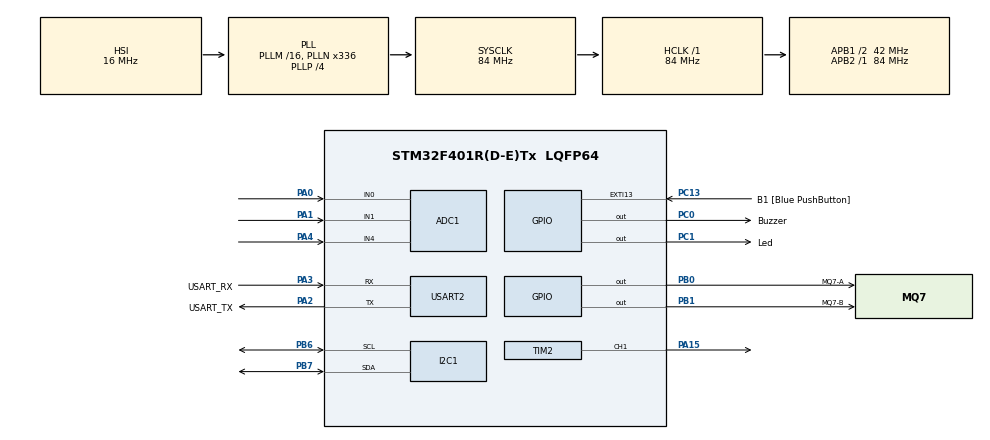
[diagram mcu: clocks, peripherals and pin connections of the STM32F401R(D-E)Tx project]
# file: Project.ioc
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ADC1.Channel-0\#ChannelRegularConversion=ADC_CHANNEL_0
ADC1.Channel-1\#ChannelRegularConversion=ADC_CHANNEL_1
ADC1.Channel-2\#ChannelRegularConversion=ADC_CHANNEL_4
ADC1.ContinuousConvMode=ENABLE
ADC1.DMAContinuousRequests=ENABLE
ADC1.DiscontinuousConvMode=DISABLE
ADC1.NbrOfConversion=3
ADC1.NbrOfConversionFlag=1
ADC1.Rank-0\#ChannelRegularConversion=1
ADC1.Rank-1\#ChannelRegularConversion=2
ADC1.Rank-2\#ChannelRegularConversion=3
ADC1.SamplingTime-0\#ChannelRegularConversion=ADC_SAMPLETIME_480CYCLES
ADC1.SamplingTime-1\#ChannelRegularConversion=ADC_SAMPLETIME_480CYCLES
ADC1.SamplingTime-2\#ChannelRegularConversion=ADC_SAMPLETIME_480CYCLES
ADC1.ScanConvMode=ENABLE
ADC1.master=1
Dma.ADC1.0.Direction=DMA_PERIPH_TO_MEMORY
Dma.ADC1.0.FIFOMode=DMA_FIFOMODE_DISABLE
Dma.ADC1.0.Instance=DMA2_Stream0
Dma.ADC1.0.MemDataAlignment=DMA_MDATAALIGN_HALFWORD
Dma.ADC1.0.MemInc=DMA_MINC_ENABLE
Dma.ADC1.0.Mode=DMA_CIRCULAR
Dma.ADC1.0.PeriphDataAlignment=DMA_PDATAALIGN_HALFWORD
Dma.ADC1.0.PeriphInc=DMA_PINC_DISABLE
Dma.ADC1.0.Priority=DMA_PRIORITY_LOW
Dma.Request0=ADC1
Mcu.Family=STM32F4
Mcu.Name=STM32F401R(D-E)Tx
Mcu.Package=LQFP64
NVIC.DMA2_Stream0_IRQn=true\:0\:0\:false\:false\:true\:false\:true\:true
NVIC.PriorityGroup=NVIC_PRIORITYGROUP_4
PA0-WKUP.Signal=ADCx_IN0
PA1.Signal=ADCx_IN1
PA13.GPIO_Label=TMS
PA13.Mode=Serial_Wire
PA13.Signal=SYS_JTMS-SWDIO
PA14.GPIO_Label=TCK
PA14.Mode=Serial_Wire
PA14.Signal=SYS_JTCK-SWCLK
PA15.Signal=S_TIM2_CH1_ETR
PA2.GPIO_Label=USART_TX
PA2.GPIO_Mode=GPIO_MODE_AF_PP
PA2.GPIO_PuPd=GPIO_NOPULL
PA2.GPIO_Speed=GPIO_SPEED_FREQ_LOW
PA2.Mode=Asynchronous
PA2.Signal=USART2_TX
PA3.GPIO_Label=USART_RX
PA3.GPIO_Mode=GPIO_MODE_AF_PP
PA3.GPIO_PuPd=GPIO_NOPULL
PA3.GPIO_Speed=GPIO_SPEED_FREQ_LOW
PA3.Mode=Asynchronous
PA3.Signal=USART2_RX
PA4.Signal=ADCx_IN4
PB0.GPIO_Label=MQ7-A
PB0.Signal=GPIO_Output
PB1.GPIO_Label=MQ7-B
PB1.Signal=GPIO_Output
PB3.GPIO_Label=SWO
PB3.Signal=SYS_JTDO-SWO
PB6.Mode=I2C
PB6.Signal=I2C1_SCL
PB7.Mode=I2C
PB7.Signal=I2C1_SDA
PC0.GPIO_Label=Buzzer
PC0.Signal=GPIO_Output
PC1.GPIO_Label=Led
PC1.Signal=GPIO_Output
PC13-ANTI_TAMP.GPIO_Label=B1 [Blue PushButton]
PC13-ANTI_TAMP.GPIO_ModeDefaultEXTI=GPIO_MODE_IT_FALLING
PC13-ANTI_TAMP.GPIO_PuPd=GPIO_NOPULL
PC13-ANTI_TAMP.Signal=GPXTI13
PC14-OSC32_IN.Mode=LSE-External-Oscillator
PC14-OSC32_IN.Signal=RCC_OSC32_IN
PC15-OSC32_OUT.Mode=LSE-External-Oscillator
PC15-OSC32_OUT.Signal=RCC_OSC32_OUT
PH0\ -\ OSC_IN.Mode=HSE-External-Clock-Source
PH0\ -\ OSC_IN.Signal=RCC_OSC_IN
PH1\ -\ OSC_OUT.Mode=HSE-External-Clock-Source
PH1\ -\ OSC_OUT.Signal=RCC_OSC_OUT
ProjectManager.HeapSize=0x200
ProjectManager.StackSize=0x400
ProjectManager.TargetToolchain=STM32CubeIDE
RCC.48MHZClocksFreq_Value=48000000
RCC.AHBFreq_Value=84000000
RCC.APB1CLKDivider=RCC_HCLK_DIV2
RCC.APB1Freq_Value=42000000
RCC.APB1TimFreq_Value=84000000
RCC.APB2Freq_Value=84000000
RCC.APB2TimFreq_Value=84000000
RCC.CortexFreq_Value=84000000
RCC.HCLKFreq_Value=84000000
RCC.HSE_VALUE=8000000
RCC.HSI_VALUE=16000000
RCC.PLLN=336
RCC.PLLP=RCC_PLLP_DIV4
RCC.PLLQ=7
RCC.SYSCLKFreq_VALUE=84000000
RCC.SYSCLKSource=RCC_SYSCLKSOURCE_PLLCLK
RCC.VCOOutputFreq_Value=336000000
SH.ADCx_IN0.0=ADC1_IN0,IN0
SH.ADCx_IN1.0=ADC1_IN1,IN1
SH.ADCx_IN4.0=ADC1_IN4,IN4
SH.S_TIM2_CH1_ETR.0=TIM2_CH1,PWM Generation1 CH1
TIM2.Channel-PWM\ Generation1\ CH1=TIM_CHANNEL_1
TIM2.Period=999
TIM2.Prescaler=84-1
USART2.VirtualMode=VM_ASYNC
VP_TIM2_VS_ClockSourceINT.Mode=Internal
board=NUCLEO-F401RE

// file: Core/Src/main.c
/* USER CODE BEGIN Header */
/**
  ******************************************************************************
  * @file           : main.c
  * @brief          : Main program body
  ******************************************************************************
  */
/* USER CODE END Header */
#include "main.h"

/* USER CODE BEGIN Includes */
#include <stdio.h>
#include "periph_led_buzzer.h"
#include "fan_pwm.h"
#include "sensor_raw.h"
#include "adc_dma.h"
#include "temp_sensor.h"
/* USER CODE END Includes */

ADC_HandleTypeDef hadc1;
DMA_HandleTypeDef hdma_adc1;

I2C_HandleTypeDef hi2c1;

TIM_HandleTypeDef htim2;

UART_HandleTypeDef huart2;

/* USER CODE BEGIN PV */
/* --- BIẾN ĐỊNH THỜI ĐA NHIỆM --- */
uint32_t last_mq7_cycle = 0;
uint32_t last_sensor_read = 0;
uint8_t current_pwm = 0;
/* --- BIẾN LƯU TRỮ DỮ LIỆU --- */
float current_temp = 0.0;
uint16_t mq135_raw = 0;
uint16_t mq7_raw = 0;
SHT30_Data_t sht30_data;

/* --- BIẾN PID ĐIỀU KHIỂN QUẠT --- */
float Kp = 30.0;  // Tăng tốc độ phản ứng
float Ki = 0.2;   // Khử sai số tĩnh
float Kd = 0;   // Phanh ( cảm biến nhiệt dễ nhiễu nên k cần )
float setpoint_temp = 31.0; // Nhiệt độ kích hoạt

float pid_error = 0, previous_error = 0;
float integral = 0, derivative = 0;
float pid_output = 0;
/* USER CODE END PV */

void SystemClock_Config(void);
static void MX_GPIO_Init(void);
static void MX_DMA_Init(void);
static void MX_USART2_UART_Init(void);
static void MX_ADC1_Init(void);
static void MX_I2C1_Init(void);
static void MX_TIM2_Init(void);

/* USER CODE BEGIN 0 */
/* --- HÀM RETARGET PRINTF ĐỂ IN LOG LÊN PC --- */
int _write(int file, char *ptr, int len) {
    HAL_UART_Transmit(&huart2, (uint8_t*)ptr, len, HAL_MAX_DELAY);
    return len;
}
/* USER CODE END 0 */

int main(void)
{

  /* MCU Configuration--------------------------------------------------------*/

  /* Reset of all peripherals, Initializes the Flash interface and the Systick. */
  HAL_Init();

  /* Configure the system clock */
  SystemClock_Config();

  /* Initialize all configured peripherals */
  MX_GPIO_Init();
  MX_DMA_Init();
  MX_USART2_UART_Init();
  MX_ADC1_Init();
  MX_I2C1_Init();
  MX_TIM2_Init();

  /* USER CODE BEGIN 2 */
  LedBuzzer_Init();
  FanPWM_Init(&htim2);
  FanPWM_SetDuty(30); /* start with low speed */

  ADC_DMA_Init();
  SHT30_Init(&hi2c1);
  if (SHT30_Init(&hi2c1) == HAL_OK) {
        printf(">>> SHT30 CONNECTED OK! <<<\r\n");
    } else {
        printf(">>> ERROR: SHT30 NOT FOUND! CHECK WIRING OR ADDRESS! <<<\r\n");
    }
  /* USER CODE END 2 */

  /* Infinite loop */
  /* USER CODE BEGIN WHILE */
  while (1)
  {
      uint32_t current_time = HAL_GetTick();
      if (current_time - last_mq7_cycle >= 1000) {

                // 1. Đọc SHT30
              if (SHT30_Read_Temp_Humidity_NonBlocking(&hi2c1, &sht30_data) == HAL_OK) {
                  current_temp = sht30_data.temperature;
                }

                // 2. Đọc Cảm biến Khí
                MQ7_Cycle_Manager();
                mq135_raw = Get_MQ135_Raw();
                mq7_raw = Get_MQ7_Current_Raw();

                // 3. In toàn bộ thông số lên Terminal PC
                printf("{\"T\": %5.1f, \"H\": %5.1f, \"M135\": %4d, \"M7\": %4d, \"PWM\": %3d}\r\n",
                       current_temp,
                       sht30_data.humidity,
                       mq135_raw,
                       mq7_raw,
                       current_pwm);

                last_mq7_cycle = current_time;
            }

      // ---------------------------------------------------------
      // [LUỒNG 2]  XỬ LÝ CẢNH BÁO (Mỗi 200ms)
      // ---------------------------------------------------------
      if (current_time - last_sensor_read >= 200) {
    	            // --- 1. THUẬT TOÁN PID CHO QUẠT TẢN NHIỆT ---
    	            pid_error = current_temp - setpoint_temp;

    	            if (pid_error > 0) {
    	                // Nếu nhiệt độ thực tế CAO HƠN ngưỡng 31 độ
    	                // Thời gian lấy mẫu dt = 0.2 giây (200ms)
    	                integral = integral + (pid_error * 0.2);
    	                derivative = (pid_error - previous_error) / 0.2;
    	                if (integral > 100.0) integral = 100.0;
    	                pid_output = (Kp * pid_error) + (Ki * integral) + (Kd * derivative);

    	                // Khóa giới hạn băm xung PWM từ 0% đến 100%
    	                if (pid_output > 100.0) pid_output = 100.0;
    	                if (pid_output < 0.0)   pid_output = 0.0;

    	                if (pid_output >1) {   // tránh deadband
    	                	current_pwm = 20 + (uint8_t)(pid_output * 0.8);
    	                }
    	            } else {
    	                // Nếu nhiệt độ MÁT HƠN 31 độ -> Tắt quạt
    	                current_pwm = 0;
    	                integral = 0; // Reset khâu I để chống kẹt số (Wind-up)
    	            }

    	            previous_error = pid_error;

    	            // Xuất xung thực tế ra chân PA15 của quạt
    	            FanPWM_SetDuty(current_pwm);

    	            // --- 2. LOGIC CẢNH BÁO KHÍ GA ---
    	            if (mq7_raw > 1000 || mq135_raw > 400) {
    	                Led_On();
    	                 Buzzer_Beep(100);
    	            } else {
    	                Led_Off();
    	            }

    	            last_sensor_read = current_time;
    	        }
      }

    /* USER CODE END WHILE */

  }

void SystemClock_Config(void)
{
  RCC_OscInitTypeDef RCC_OscInitStruct = {0};
  RCC_ClkInitTypeDef RCC_ClkInitStruct = {0};

  __HAL_RCC_PWR_CLK_ENABLE();
  __HAL_PWR_VOLTAGESCALING_CONFIG(PWR_REGULATOR_VOLTAGE_SCALE2);

  RCC_OscInitStruct.OscillatorType = RCC_OSCILLATORTYPE_HSI;
  RCC_OscInitStruct.HSIState = RCC_HSI_ON;
  RCC_OscInitStruct.HSICalibrationValue = RCC_HSICALIBRATION_DEFAULT;
  RCC_OscInitStruct.PLL.PLLState = RCC_PLL_ON;
  RCC_OscInitStruct.PLL.PLLSource = RCC_PLLSOURCE_HSI;
  RCC_OscInitStruct.PLL.PLLM = 16;
  RCC_OscInitStruct.PLL.PLLN = 336;
  RCC_OscInitStruct.PLL.PLLP = RCC_PLLP_DIV4;
  RCC_OscInitStruct.PLL.PLLQ = 7;
  if (HAL_RCC_OscConfig(&RCC_OscInitStruct) != HAL_OK)
  {
    Error_Handler();
  }

  RCC_ClkInitStruct.ClockType = RCC_CLOCKTYPE_HCLK|RCC_CLOCKTYPE_SYSCLK
                              |RCC_CLOCKTYPE_PCLK1|RCC_CLOCKTYPE_PCLK2;
  RCC_ClkInitStruct.SYSCLKSource = RCC_SYSCLKSOURCE_PLLCLK;
  RCC_ClkInitStruct.AHBCLKDivider = RCC_SYSCLK_DIV1;
  RCC_ClkInitStruct.APB1CLKDivider = RCC_HCLK_DIV2;
  RCC_ClkInitStruct.APB2CLKDivider = RCC_HCLK_DIV1;

  if (HAL_RCC_ClockConfig(&RCC_ClkInitStruct, FLASH_LATENCY_2) != HAL_OK)
  {
    Error_Handler();
  }
}

static void MX_ADC1_Init(void)
{
  ADC_ChannelConfTypeDef sConfig = {0};

  hadc1.Instance = ADC1;
  hadc1.Init.ClockPrescaler = ADC_CLOCK_SYNC_PCLK_DIV4;
  hadc1.Init.Resolution = ADC_RESOLUTION_12B;
  hadc1.Init.ScanConvMode = ENABLE;
  hadc1.Init.ContinuousConvMode = ENABLE;
  hadc1.Init.DiscontinuousConvMode = DISABLE;
  hadc1.Init.ExternalTrigConvEdge = ADC_EXTERNALTRIGCONVEDGE_NONE;
  hadc1.Init.ExternalTrigConv = ADC_SOFTWARE_START;
  hadc1.Init.DataAlign = ADC_DATAALIGN_RIGHT;
  hadc1.Init.NbrOfConversion = 3;
  hadc1.Init.DMAContinuousRequests = ENABLE;
  hadc1.Init.EOCSelection = ADC_EOC_SINGLE_CONV;
  if (HAL_ADC_Init(&hadc1) != HAL_OK)
  {
    Error_Handler();
  }

  sConfig.Channel = ADC_CHANNEL_0;
  sConfig.Rank = 1;
  sConfig.SamplingTime = ADC_SAMPLETIME_480CYCLES;
  if (HAL_ADC_ConfigChannel(&hadc1, &sConfig) != HAL_OK)
  {
    Error_Handler();
  }

  sConfig.Channel = ADC_CHANNEL_1;
  sConfig.Rank = 2;
  if (HAL_ADC_ConfigChannel(&hadc1, &sConfig) != HAL_OK)
  {
    Error_Handler();
  }

  sConfig.Channel = ADC_CHANNEL_4;
  sConfig.Rank = 3;
  if (HAL_ADC_ConfigChannel(&hadc1, &sConfig) != HAL_OK)
  {
    Error_Handler();
  }
}

static void MX_I2C1_Init(void)
{
  hi2c1.Instance = I2C1;
  hi2c1.Init.ClockSpeed = 100000;
  hi2c1.Init.DutyCycle = I2C_DUTYCYCLE_2;
  hi2c1.Init.OwnAddress1 = 0;
  hi2c1.Init.AddressingMode = I2C_ADDRESSINGMODE_7BIT;
  hi2c1.Init.DualAddressMode = I2C_DUALADDRESS_DISABLE;
  hi2c1.Init.OwnAddress2 = 0;
  hi2c1.Init.GeneralCallMode = I2C_GENERALCALL_DISABLE;
  hi2c1.Init.NoStretchMode = I2C_NOSTRETCH_DISABLE;
  if (HAL_I2C_Init(&hi2c1) != HAL_OK)
  {
    Error_Handler();
  }
}

static void MX_TIM2_Init(void)
{
  TIM_ClockConfigTypeDef sClockSourceConfig = {0};
  TIM_MasterConfigTypeDef sMasterConfig = {0};
  TIM_OC_InitTypeDef sConfigOC = {0};

  htim2.Instance = TIM2;
  htim2.Init.Prescaler = 84-1;
  htim2.Init.CounterMode = TIM_COUNTERMODE_UP;
  htim2.Init.Period = 999;
  htim2.Init.ClockDivision = TIM_CLOCKDIVISION_DIV1;
  htim2.Init.AutoReloadPreload = TIM_AUTORELOAD_PRELOAD_DISABLE;
  if (HAL_TIM_Base_Init(&htim2) != HAL_OK)
  {
    Error_Handler();
  }
  sClockSourceConfig.ClockSource = TIM_CLOCKSOURCE_INTERNAL;
  if (HAL_TIM_ConfigClockSource(&htim2, &sClockSourceConfig) != HAL_OK)
  {
    Error_Handler();
  }
  if (HAL_TIM_PWM_Init(&htim2) != HAL_OK)
  {
    Error_Handler();
  }
  sMasterConfig.MasterOutputTrigger = TIM_TRGO_RESET;
  sMasterConfig.MasterSlaveMode = TIM_MASTERSLAVEMODE_DISABLE;
  if (HAL_TIMEx_MasterConfigSynchronization(&htim2, &sMasterConfig) != HAL_OK)
  {
    Error_Handler();
  }
  sConfigOC.OCMode = TIM_OCMODE_PWM1;
  sConfigOC.Pulse = 0;
  sConfigOC.OCPolarity = TIM_OCPOLARITY_HIGH;
  sConfigOC.OCFastMode = TIM_OCFAST_DISABLE;
  if (HAL_TIM_PWM_ConfigChannel(&htim2, &sConfigOC, TIM_CHANNEL_1) != HAL_OK)
  {
    Error_Handler();
  }
  HAL_TIM_MspPostInit(&htim2);
}

static void MX_USART2_UART_Init(void)
{
  huart2.Instance = USART2;
  huart2.Init.BaudRate = 115200;
  huart2.Init.WordLength = UART_WORDLENGTH_8B;
  huart2.Init.StopBits = UART_STOPBITS_1;
  huart2.Init.Parity = UART_PARITY_NONE;
  huart2.Init.Mode = UART_MODE_TX_RX;
  huart2.Init.HwFlowCtl = UART_HWCONTROL_NONE;
  huart2.Init.OverSampling = UART_OVERSAMPLING_16;
  if (HAL_UART_Init(&huart2) != HAL_OK)
  {
    Error_Handler();
  }
}

static void MX_DMA_Init(void)
{
  __HAL_RCC_DMA2_CLK_ENABLE();
  HAL_NVIC_SetPriority(DMA2_Stream0_IRQn, 0, 0);
  HAL_NVIC_EnableIRQ(DMA2_Stream0_IRQn);
}

static void MX_GPIO_Init(void)
{
  GPIO_InitTypeDef GPIO_InitStruct = {0};

  __HAL_RCC_GPIOC_CLK_ENABLE();
  __HAL_RCC_GPIOH_CLK_ENABLE();
  __HAL_RCC_GPIOA_CLK_ENABLE();
  __HAL_RCC_GPIOB_CLK_ENABLE();

  HAL_GPIO_WritePin(GPIOC, Buzzer_Pin|Led_Pin, GPIO_PIN_RESET);
  HAL_GPIO_WritePin(LD2_GPIO_Port, LD2_Pin, GPIO_PIN_RESET);
  HAL_GPIO_WritePin(GPIOB, MQ7_A_Pin|MQ7_B_Pin, GPIO_PIN_RESET);

  GPIO_InitStruct.Pin = B1_Pin;
  GPIO_InitStruct.Mode = GPIO_MODE_IT_FALLING;
  GPIO_InitStruct.Pull = GPIO_NOPULL;
  HAL_GPIO_Init(B1_GPIO_Port, &GPIO_InitStruct);

  GPIO_InitStruct.Pin = Buzzer_Pin|Led_Pin;
  GPIO_InitStruct.Mode = GPIO_MODE_OUTPUT_PP;
  GPIO_InitStruct.Pull = GPIO_NOPULL;
  GPIO_InitStruct.Speed = GPIO_SPEED_FREQ_LOW;
  HAL_GPIO_Init(GPIOC, &GPIO_InitStruct);

  GPIO_InitStruct.Pin = LD2_Pin;
  GPIO_InitStruct.Mode = GPIO_MODE_OUTPUT_PP;
  GPIO_InitStruct.Pull = GPIO_NOPULL;
  GPIO_InitStruct.Speed = GPIO_SPEED_FREQ_LOW;
  HAL_GPIO_Init(LD2_GPIO_Port, &GPIO_InitStruct);

  GPIO_InitStruct.Pin = MQ7_A_Pin|MQ7_B_Pin;
  GPIO_InitStruct.Mode = GPIO_MODE_OUTPUT_PP;
  GPIO_InitStruct.Pull = GPIO_NOPULL;
  GPIO_InitStruct.Speed = GPIO_SPEED_FREQ_LOW;
  HAL_GPIO_Init(GPIOB, &GPIO_InitStruct);
}

void Error_Handler(void)
{
  __disable_irq();
  while (1)
  {
  }
}
